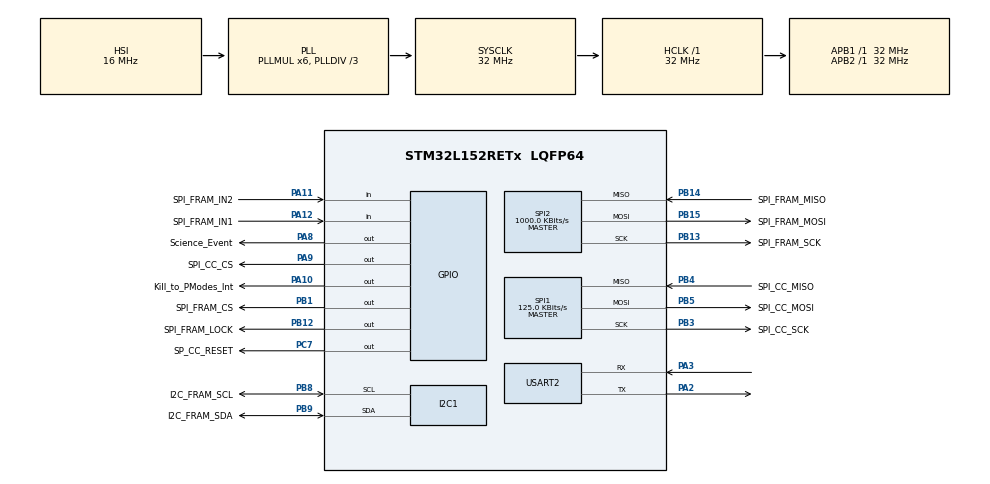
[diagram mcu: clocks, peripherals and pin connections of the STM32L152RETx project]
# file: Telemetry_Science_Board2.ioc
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Mcu.Family=STM32L1
Mcu.Name=STM32L152RETx
Mcu.Package=LQFP64
NVIC.PriorityGroup=NVIC_PRIORITYGROUP_0
PA10.GPIO_Label=Kill_to_PModes_Int
PA10.Signal=GPIO_Output
PA11.GPIO_Label=SPI_FRAM_IN2
PA11.Signal=GPIO_Input
PA12.GPIO_Label=SPI_FRAM_IN1
PA12.Signal=GPIO_Input
PA2.Mode=Asynchronous
PA2.Signal=USART2_TX
PA3.Mode=Asynchronous
PA3.Signal=USART2_RX
PA8.GPIO_Label=Science_Event
PA8.Signal=GPIO_Output
PA9.GPIO_Label=SPI_CC_CS
PA9.Signal=GPIO_Output
PB1.GPIO_Label=SPI_FRAM_CS
PB1.Signal=GPIO_Output
PB12.GPIO_Label=SPI_FRAM_LOCK
PB12.Signal=GPIO_Output
PB13.GPIO_Label=SPI_FRAM_SCK
PB13.Mode=Full_Duplex_Master
PB13.Signal=SPI2_SCK
PB14.GPIO_Label=SPI_FRAM_MISO
PB14.Mode=Full_Duplex_Master
PB14.Signal=SPI2_MISO
PB15.GPIO_Label=SPI_FRAM_MOSI
PB15.Mode=Full_Duplex_Master
PB15.Signal=SPI2_MOSI
PB3.GPIO_Label=SPI_CC_SCK
PB3.Mode=Full_Duplex_Master
PB3.Signal=SPI1_SCK
PB4.GPIO_Label=SPI_CC_MISO
PB4.Mode=Full_Duplex_Master
PB4.Signal=SPI1_MISO
PB5.GPIO_Label=SPI_CC_MOSI
PB5.Mode=Full_Duplex_Master
PB5.Signal=SPI1_MOSI
PB8.GPIO_Label=I2C_FRAM_SCL
PB8.Mode=I2C
PB8.Signal=I2C1_SCL
PB9.GPIO_Label=I2C_FRAM_SDA
PB9.Mode=I2C
PB9.Signal=I2C1_SDA
PC7.GPIO_Label=SP_CC_RESET
PC7.Signal=GPIO_Output
ProjectManager.HeapSize=0x200
ProjectManager.StackSize=0x400
ProjectManager.TargetToolchain=MDK-ARM V5
RCC.48MHZClocksFreq_Value=48000000
RCC.AHBFreq_Value=32000000
RCC.APB1Freq_Value=32000000
RCC.APB1TimFreq_Value=32000000
RCC.APB2Freq_Value=32000000
RCC.APB2TimFreq_Value=32000000
RCC.HCLKFreq_Value=32000000
RCC.HSE_VALUE=8000000
RCC.HSI_VALUE=16000000
RCC.LSE_VALUE=32768
RCC.MSI_VALUE=2097000
RCC.PLLDIV=RCC_PLL_DIV3
RCC.PLLMUL=RCC_PLL_MUL6
RCC.RTCClockSelectionVirtual=RCC_RTCCLKSOURCE_LSE
RCC.SYSCLKFreq_VALUE=32000000
RCC.SYSCLKSource=RCC_SYSCLKSOURCE_PLLCLK
RCC.USBOutput=48000000
RCC.VCOOutputFreq_Value=96000000
SPI1.BaudRatePrescaler=SPI_BAUDRATEPRESCALER_256
SPI1.CalculateBaudRate=125.0 KBits/s
SPI1.Direction=SPI_DIRECTION_2LINES
SPI1.Mode=SPI_MODE_MASTER
SPI1.VirtualType=VM_MASTER
SPI2.BaudRatePrescaler=SPI_BAUDRATEPRESCALER_32
SPI2.CalculateBaudRate=1000.0 KBits/s
SPI2.Direction=SPI_DIRECTION_2LINES
SPI2.Mode=SPI_MODE_MASTER
SPI2.VirtualType=VM_MASTER
USART2.VirtualMode=VM_ASYNC
board=NUCLEO-L152RE

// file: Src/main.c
/* USER CODE BEGIN Header */
/**
  ******************************************************************************
  * @file           : main.c
  * @brief          : Main program body
  ******************************************************************************
  ** This notice applies to any and all portions of this file
  * that are not between comment pairs USER CODE BEGIN and
  * USER CODE END. Other portions of this file, whether
  * inserted by the user or by software development tools
  * are owned by their respective copyright owners.
  *
  * COPYRIGHT(c) 2019 STMicroelectronics
  *
  * Redistribution and use in source and binary forms, with or without modification,
  * are permitted provided that the following conditions are met:
  *   1. Redistributions of source code must retain the above copyright notice,
  *      this list of conditions and the following disclaimer.
  *   2. Redistributions in binary form must reproduce the above copyright notice,
  *      this list of conditions and the following disclaimer in the documentation
  *      and/or other materials provided with the distribution.
  *   3. Neither the name of STMicroelectronics nor the names of its contributors
  *      may be used to endorse or promote products derived from this software
  *      without specific prior written permission.
  *
  * THIS SOFTWARE IS PROVIDED BY THE COPYRIGHT HOLDERS AND CONTRIBUTORS "AS IS"
  * AND ANY EXPRESS OR IMPLIED WARRANTIES, INCLUDING, BUT NOT LIMITED TO, THE
  * IMPLIED WARRANTIES OF MERCHANTABILITY AND FITNESS FOR A PARTICULAR PURPOSE ARE
  * DISCLAIMED. IN NO EVENT SHALL THE COPYRIGHT HOLDER OR CONTRIBUTORS BE LIABLE
  * FOR ANY DIRECT, INDIRECT, INCIDENTAL, SPECIAL, EXEMPLARY, OR CONSEQUENTIAL
  * DAMAGES (INCLUDING, BUT NOT LIMITED TO, PROCUREMENT OF SUBSTITUTE GOODS OR
  * SERVICES; LOSS OF USE, DATA, OR PROFITS; OR BUSINESS INTERRUPTION) HOWEVER
  * CAUSED AND ON ANY THEORY OF LIABILITY, WHETHER IN CONTRACT, STRICT LIABILITY,
  * OR TORT (INCLUDING NEGLIGENCE OR OTHERWISE) ARISING IN ANY WAY OUT OF THE USE
  * OF THIS SOFTWARE, EVEN IF ADVISED OF THE POSSIBILITY OF SUCH DAMAGE.
  *
  ******************************************************************************
  */
/* USER CODE END Header */

#include "main.h"

/* USER CODE BEGIN Includes */
#include "Sci_Tel_SM.h"
/* USER CODE END Includes */

I2C_HandleTypeDef hi2c1;

SPI_HandleTypeDef hspi1;
SPI_HandleTypeDef hspi2;

UART_HandleTypeDef huart2;

void SystemClock_Config(void);
static void MX_GPIO_Init(void);
static void MX_USART2_UART_Init(void);
static void MX_SPI1_Init(void);
static void MX_SPI2_Init(void);
static void MX_I2C1_Init(void);

int main(void)
{

  /* MCU Configuration--------------------------------------------------------*/

  /* Reset of all peripherals, Initializes the Flash interface and the Systick. */
  HAL_Init();

  /* Configure the system clock */
  SystemClock_Config();

  /* Initialize all configured peripherals */
  MX_GPIO_Init();
  MX_USART2_UART_Init();
  MX_SPI1_Init();
  MX_SPI2_Init();
  MX_I2C1_Init();
  /* USER CODE BEGIN 2 */

	Sci_Tel_SM_Init(&hi2c1, &hspi1, &hspi2, &huart2);

  /* USER CODE END 2 */

  /* Infinite loop */
  /* USER CODE BEGIN WHILE */
  while (1)
  {
		Sci_Tel_SM_Run();
    /* USER CODE END WHILE */

  }
}

void SystemClock_Config(void)
{
  RCC_OscInitTypeDef RCC_OscInitStruct = {0};
  RCC_ClkInitTypeDef RCC_ClkInitStruct = {0};

  /** Configure the main internal regulator output voltage
  */
  __HAL_PWR_VOLTAGESCALING_CONFIG(PWR_REGULATOR_VOLTAGE_SCALE1);
  /** Initializes the CPU, AHB and APB busses clocks
  */
  RCC_OscInitStruct.OscillatorType = RCC_OSCILLATORTYPE_HSI;
  RCC_OscInitStruct.HSIState = RCC_HSI_ON;
  RCC_OscInitStruct.HSICalibrationValue = RCC_HSICALIBRATION_DEFAULT;
  RCC_OscInitStruct.PLL.PLLState = RCC_PLL_ON;
  RCC_OscInitStruct.PLL.PLLSource = RCC_PLLSOURCE_HSI;
  RCC_OscInitStruct.PLL.PLLMUL = RCC_PLL_MUL6;
  RCC_OscInitStruct.PLL.PLLDIV = RCC_PLL_DIV3;
  if (HAL_RCC_OscConfig(&RCC_OscInitStruct) != HAL_OK)
  {
    Error_Handler();
  }
  /** Initializes the CPU, AHB and APB busses clocks
  */
  RCC_ClkInitStruct.ClockType = RCC_CLOCKTYPE_HCLK|RCC_CLOCKTYPE_SYSCLK
                              |RCC_CLOCKTYPE_PCLK1|RCC_CLOCKTYPE_PCLK2;
  RCC_ClkInitStruct.SYSCLKSource = RCC_SYSCLKSOURCE_PLLCLK;
  RCC_ClkInitStruct.AHBCLKDivider = RCC_SYSCLK_DIV1;
  RCC_ClkInitStruct.APB1CLKDivider = RCC_HCLK_DIV1;
  RCC_ClkInitStruct.APB2CLKDivider = RCC_HCLK_DIV1;

  if (HAL_RCC_ClockConfig(&RCC_ClkInitStruct, FLASH_LATENCY_1) != HAL_OK)
  {
    Error_Handler();
  }
}

static void MX_I2C1_Init(void)
{

  hi2c1.Instance = I2C1;
  hi2c1.Init.ClockSpeed = 100000;
  hi2c1.Init.DutyCycle = I2C_DUTYCYCLE_2;
  hi2c1.Init.OwnAddress1 = 0;
  hi2c1.Init.AddressingMode = I2C_ADDRESSINGMODE_7BIT;
  hi2c1.Init.DualAddressMode = I2C_DUALADDRESS_DISABLE;
  hi2c1.Init.OwnAddress2 = 0;
  hi2c1.Init.GeneralCallMode = I2C_GENERALCALL_DISABLE;
  hi2c1.Init.NoStretchMode = I2C_NOSTRETCH_DISABLE;
  if (HAL_I2C_Init(&hi2c1) != HAL_OK)
  {
    Error_Handler();
  }

}

static void MX_SPI1_Init(void)
{

  /* SPI1 parameter configuration*/
  hspi1.Instance = SPI1;
  hspi1.Init.Mode = SPI_MODE_MASTER;
  hspi1.Init.Direction = SPI_DIRECTION_2LINES;
  hspi1.Init.DataSize = SPI_DATASIZE_8BIT;
  hspi1.Init.CLKPolarity = SPI_POLARITY_LOW;
  hspi1.Init.CLKPhase = SPI_PHASE_1EDGE;
  hspi1.Init.NSS = SPI_NSS_SOFT;
  hspi1.Init.BaudRatePrescaler = SPI_BAUDRATEPRESCALER_256;
  hspi1.Init.FirstBit = SPI_FIRSTBIT_MSB;
  hspi1.Init.TIMode = SPI_TIMODE_DISABLE;
  hspi1.Init.CRCCalculation = SPI_CRCCALCULATION_DISABLE;
  hspi1.Init.CRCPolynomial = 10;
  if (HAL_SPI_Init(&hspi1) != HAL_OK)
  {
    Error_Handler();
  }

}

static void MX_SPI2_Init(void)
{

  /* SPI2 parameter configuration*/
  hspi2.Instance = SPI2;
  hspi2.Init.Mode = SPI_MODE_MASTER;
  hspi2.Init.Direction = SPI_DIRECTION_2LINES;
  hspi2.Init.DataSize = SPI_DATASIZE_8BIT;
  hspi2.Init.CLKPolarity = SPI_POLARITY_LOW;
  hspi2.Init.CLKPhase = SPI_PHASE_1EDGE;
  hspi2.Init.NSS = SPI_NSS_SOFT;
  hspi2.Init.BaudRatePrescaler = SPI_BAUDRATEPRESCALER_32;
  hspi2.Init.FirstBit = SPI_FIRSTBIT_MSB;
  hspi2.Init.TIMode = SPI_TIMODE_DISABLE;
  hspi2.Init.CRCCalculation = SPI_CRCCALCULATION_DISABLE;
  hspi2.Init.CRCPolynomial = 10;
  if (HAL_SPI_Init(&hspi2) != HAL_OK)
  {
    Error_Handler();
  }

}

static void MX_USART2_UART_Init(void)
{

  huart2.Instance = USART2;
  huart2.Init.BaudRate = 115200;
  huart2.Init.WordLength = UART_WORDLENGTH_8B;
  huart2.Init.StopBits = UART_STOPBITS_1;
  huart2.Init.Parity = UART_PARITY_NONE;
  huart2.Init.Mode = UART_MODE_TX_RX;
  huart2.Init.HwFlowCtl = UART_HWCONTROL_NONE;
  huart2.Init.OverSampling = UART_OVERSAMPLING_16;
  if (HAL_UART_Init(&huart2) != HAL_OK)
  {
    Error_Handler();
  }

}

static void MX_GPIO_Init(void)
{
  GPIO_InitTypeDef GPIO_InitStruct = {0};

  /* GPIO Ports Clock Enable */
  __HAL_RCC_GPIOA_CLK_ENABLE();
  __HAL_RCC_GPIOB_CLK_ENABLE();
  __HAL_RCC_GPIOC_CLK_ENABLE();

  /*Configure GPIO pin Output Level */
  HAL_GPIO_WritePin(GPIOB, SPI_FRAM_CS_Pin|SPI_FRAM_LOCK_Pin, GPIO_PIN_RESET);

  /*Configure GPIO pin Output Level */
  HAL_GPIO_WritePin(SP_CC_RESET_GPIO_Port, SP_CC_RESET_Pin, GPIO_PIN_RESET);

  /*Configure GPIO pin Output Level */
  HAL_GPIO_WritePin(GPIOA, Science_Event_Pin|SPI_CC_CS_Pin|Kill_to_PModes_Int_Pin, GPIO_PIN_RESET);

  /*Configure GPIO pins : SPI_FRAM_CS_Pin SPI_FRAM_LOCK_Pin */
  GPIO_InitStruct.Pin = SPI_FRAM_CS_Pin|SPI_FRAM_LOCK_Pin;
  GPIO_InitStruct.Mode = GPIO_MODE_OUTPUT_PP;
  GPIO_InitStruct.Pull = GPIO_NOPULL;
  GPIO_InitStruct.Speed = GPIO_SPEED_FREQ_LOW;
  HAL_GPIO_Init(GPIOB, &GPIO_InitStruct);

  /*Configure GPIO pin : SP_CC_RESET_Pin */
  GPIO_InitStruct.Pin = SP_CC_RESET_Pin;
  GPIO_InitStruct.Mode = GPIO_MODE_OUTPUT_PP;
  GPIO_InitStruct.Pull = GPIO_NOPULL;
  GPIO_InitStruct.Speed = GPIO_SPEED_FREQ_LOW;
  HAL_GPIO_Init(SP_CC_RESET_GPIO_Port, &GPIO_InitStruct);

  /*Configure GPIO pins : Science_Event_Pin SPI_CC_CS_Pin Kill_to_PModes_Int_Pin */
  GPIO_InitStruct.Pin = Science_Event_Pin|SPI_CC_CS_Pin|Kill_to_PModes_Int_Pin;
  GPIO_InitStruct.Mode = GPIO_MODE_OUTPUT_PP;
  GPIO_InitStruct.Pull = GPIO_NOPULL;
  GPIO_InitStruct.Speed = GPIO_SPEED_FREQ_LOW;
  HAL_GPIO_Init(GPIOA, &GPIO_InitStruct);

  /*Configure GPIO pins : SPI_FRAM_IN2_Pin SPI_FRAM_IN1_Pin */
  GPIO_InitStruct.Pin = SPI_FRAM_IN2_Pin|SPI_FRAM_IN1_Pin;
  GPIO_InitStruct.Mode = GPIO_MODE_INPUT;
  GPIO_InitStruct.Pull = GPIO_NOPULL;
  HAL_GPIO_Init(GPIOA, &GPIO_InitStruct);

}

void Error_Handler(void)
{
}

/************************ (C) COPYRIGHT STMicroelectronics *****END OF FILE****/
